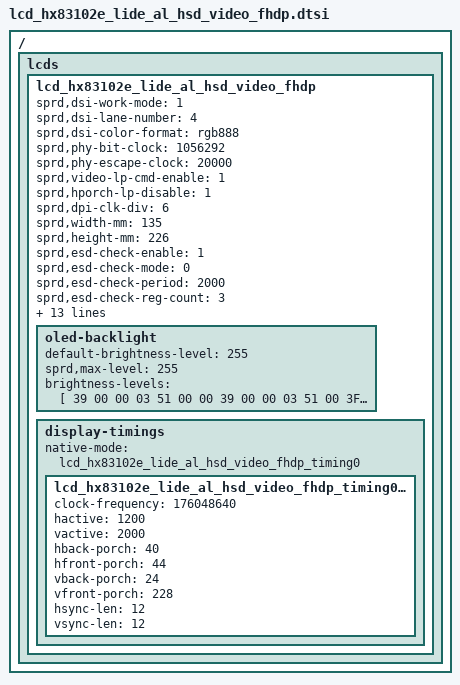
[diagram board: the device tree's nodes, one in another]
/ {
	fragment {
		target-path = "/";
		__overlay__ {
			lcds {
				lcd_hx83102e_lide_al_hsd_video_fhdp: lcd_hx83102e_lide_al_hsd_video_fhdp {

					sprd,dsi-work-mode = <1>; /* video burst mode*/
					sprd,dsi-lane-number = <4>;
					sprd,dsi-color-format = "rgb888";

					sprd,phy-bit-clock = <1056292>;  /* kbps */
					sprd,phy-escape-clock = <20000>;/* kHz */

					sprd,video-lp-cmd-enable = <1>;
					sprd,hporch-lp-disable = <1>;
					sprd,dpi-clk-div = <6>;

					sprd,width-mm = <135>;
					sprd,height-mm = <226>;

					sprd,esd-check-enable = <1>;
					sprd,esd-check-mode = <0>;
					sprd,esd-check-period = <2000>;
					sprd,esd-check-reg-count = <3>;
					sprd,esd-check-register = [0A 09 45];
					sprd,esd-check-value-len = <1 3 1>;
					sprd,esd-check-value = [9D 80 73 06 08];

					sprd,reset-on-sequence = <1 5>, <0 15>, <1 30>;
					sprd,reset-off-sequence = <1 5>;

					sprd,initial-command = [
						39 01 00 04 B9 83 10 2E
						39 01 00 03 E1 00 00
						39 01 00 02 E2 03
						39 01 00 02 E9 CD
						39 01 00 02 BB 01
						39 01 00 02 E9 00
						39 01 00 05 D1 67 0C FF 05
						39 01 00 12 B1 10 FA AF AF 31 31 B1 6C 31 36 36 36 36 22 21 15 00
						39 01 00 11 B2 00 B0 47 D0 00 22 E4 26 20 00 00 00 15 20 57 00
						39 01 00 11 B4 10 10 01 01 88 70 68 50 08 8F 07 58 00 FF 00 FF
						39 01 00 03 D2 31 31
						39 01 00 08 BF FC 85 80 9C 36 00 1C
						39 01 00 2C D3 00 00 00 00 3C 3D 00 00 00 27 27 22 0F 23 23 04 00 32 10 21 00 21 32 17 F5 07 F5 32 10 08 00 00 00 00 2B 50 B6 C8 2C 4F B6 C8 0F
						39 01 00 2F E0 00 09 18 22 2B 50 67 6E 72 6C 80 81 81 8C 87 8F 98 AC AB 54 5B 66 73 00 09 18 22 2B 50 67 6E 72 6C 80 81 81 8C 87 8F 98 AC AB 54 5B 66 73
						39 01 00 02 BD 01
						39 01 00 0A CB 80 36 12 16 C0 28 54 84 22
						39 01 00 0C D3 01 00 F8 00 00 11 10 00 0A 00 01
						39 01 00 02 BD 02
						39 01 00 07 B4 4E 00 33 11 33 88
						39 01 00 04 BF F2 00 02
						39 01 00 02 BD 00
						39 01 00 0F C0 27 27 44 11 A2 17 00 86 00 00 00 00 63 63
						39 01 00 2D D5 18 18 18 18 18 18 18 18 18 18 19 19 3A 3A 1A 1A 1B 1B 00 01 02 03 04 05 06 07 20 21 24 25 18 18 18 18 18 18 18 18 18 18 18 18 18 18
						39 01 00 2D D6 18 18 18 18 18 18 18 18 18 18 3A 3A 19 19 1A 1A 1B 1B 07 06 05 04 03 02 01 00 25 24 21 20 18 18 18 18 18 18 18 18 18 18 18 18 18 18
						39 01 00 04 D0 07 04 05
						39 01 00 18 E7 12 13 02 02 55 00 0E 0E 00 26 29 72 1C 72 01 27 00 00 00 00 17 00 68
						39 01 00 02 BD 01
						39 01 00 08 E7 01 30 01 94 0D B5 0E
						39 01 00 02 BD 02
						39 01 00 1D E7 FF 01 FD 01 00 00 22 00 00 00 00 00 00 00 00 00 00 00 00 00 00 00 00 00 81 00 02 40
						39 01 00 02 BD 01
						39 01 00 0D D8 FF FF FF FF FF F0 FF FF FF FF FF F0
						39 01 00 02 BD 02
						39 01 00 0D D8 FF FF FF FF FF F0 FF FF FF FF FF F0
						39 01 00 02 BD 00
						39 01 00 02 CC 0E	//old 02 Display flip 180 degrees 0E
						39 01 00 09 BA 70 03 A8 83 F2 00 C0 0D
						39 01 00 02 BD 03
						39 01 00 02 B2 80
						39 01 00 02 BD 00
						39 01 00 07 C8 00 04 04 00 00 82
						39 01 00 02 BD 00
						39 01 00 02 53 2C
						39 01 00 04 C9 00 0C 3A
						39 01 00 02 35 00
						39 01 00 04 B9 00 00 00
						05 46 00 01 11
						05 14 00 01 29
						];
					sprd,sleep-in-command = [
						39  00 00 04 B9 83 10 2E
						39  00 00 12 B1 10 FA AF AF 31 31 B1 00 31 36 36 36 36 22 21 15 00
						05  14 00 01 28
						05  46 00 01 10
						];
					sprd,deep-sleep-in-command = [
						39  00 00 04 B9 83 10 2E
						39  00 00 12 B1 10 FA AF AF 31 31 B1 00 31 36 36 36 36 22 21 15 00
						05  14 00 02 28 00
						05  46 00 02 10 00
						39  00 00 04 B9 83 10 2E
						15  14 00 02 B1 11
						];
					sprd,sleep-out-command = [
						23 78 00 01 11
						23 14 00 01 29
						];

					oled-backlight {
						default-brightness-level = <255>;
						sprd,max-level = <255>;

						brightness-levels = [
							39 00 00 03 51 00 00
							39 00 00 03 51 00 3F
							39 00 00 03 51 00 3F
							39 00 00 03 51 00 3F
							39 00 00 03 51 00 4F
							39 00 00 03 51 00 5F
							39 00 00 03 51 00 6F
							39 00 00 03 51 00 7F
							39 00 00 03 51 00 8F
							39 00 00 03 51 00 9F
							39 00 00 03 51 00 AF
							39 00 00 03 51 00 BF
							39 00 00 03 51 00 CF
							39 00 00 03 51 00 DF
							39 00 00 03 51 00 EF
							39 00 00 03 51 00 FF
							39 00 00 03 51 01 0F
							39 00 00 03 51 01 1F
							39 00 00 03 51 01 2F
							39 00 00 03 51 01 3F
							39 00 00 03 51 01 4F
							39 00 00 03 51 01 5F
							39 00 00 03 51 01 6F
							39 00 00 03 51 01 7F
							39 00 00 03 51 01 8F
							39 00 00 03 51 01 9F
							39 00 00 03 51 01 AF
							39 00 00 03 51 01 BF
							39 00 00 03 51 01 CF
							39 00 00 03 51 01 DF
							39 00 00 03 51 01 EF
							39 00 00 03 51 01 FF
							39 00 00 03 51 02 0F
							39 00 00 03 51 02 1F
							39 00 00 03 51 02 2F
							39 00 00 03 51 02 3F
							39 00 00 03 51 02 4F
							39 00 00 03 51 02 5F
							39 00 00 03 51 02 6F
							39 00 00 03 51 02 7F
							39 00 00 03 51 02 8F
							39 00 00 03 51 02 9F
							39 00 00 03 51 02 AF
							39 00 00 03 51 02 BF
							39 00 00 03 51 02 CF
							39 00 00 03 51 02 DF
							39 00 00 03 51 02 EF
							39 00 00 03 51 02 FF
							39 00 00 03 51 03 0F
							39 00 00 03 51 03 1F
							39 00 00 03 51 03 2F
							39 00 00 03 51 03 3F
							39 00 00 03 51 03 4F
							39 00 00 03 51 03 5F
							39 00 00 03 51 03 6F
							39 00 00 03 51 03 7F
							39 00 00 03 51 03 8F
							39 00 00 03 51 03 9F
							39 00 00 03 51 03 AF
							39 00 00 03 51 03 BF
							39 00 00 03 51 03 CF
							39 00 00 03 51 03 DF
							39 00 00 03 51 03 EF
							39 00 00 03 51 03 FF
							39 00 00 03 51 04 0F
							39 00 00 03 51 04 1F
							39 00 00 03 51 04 2F
							39 00 00 03 51 04 3F
							39 00 00 03 51 04 4F
							39 00 00 03 51 04 5F
							39 00 00 03 51 04 6F
							39 00 00 03 51 04 7F
							39 00 00 03 51 04 8F
							39 00 00 03 51 04 9F
							39 00 00 03 51 04 AF
							39 00 00 03 51 04 BF
							39 00 00 03 51 04 CF
							39 00 00 03 51 04 DF
							39 00 00 03 51 04 EF
							39 00 00 03 51 04 FF
							39 00 00 03 51 05 0F
							39 00 00 03 51 05 1F
							39 00 00 03 51 05 2F
							39 00 00 03 51 05 3F
							39 00 00 03 51 05 4F
							39 00 00 03 51 05 5F
							39 00 00 03 51 05 6F
							39 00 00 03 51 05 7F
							39 00 00 03 51 05 8F
							39 00 00 03 51 05 9F
							39 00 00 03 51 05 AF
							39 00 00 03 51 05 BF
							39 00 00 03 51 05 CF
							39 00 00 03 51 05 DF
							39 00 00 03 51 05 EF
							39 00 00 03 51 05 FF
							39 00 00 03 51 06 0F
							39 00 00 03 51 06 1F
							39 00 00 03 51 06 2F
							39 00 00 03 51 06 3F
							39 00 00 03 51 06 4F
							39 00 00 03 51 06 5F
							39 00 00 03 51 06 6F
							39 00 00 03 51 06 7F
							39 00 00 03 51 06 8F
							39 00 00 03 51 06 9F
							39 00 00 03 51 06 AF
							39 00 00 03 51 06 BF
							39 00 00 03 51 06 CF
							39 00 00 03 51 06 DF
							39 00 00 03 51 06 EF
							39 00 00 03 51 06 FF
							39 00 00 03 51 07 0F
							39 00 00 03 51 07 1F
							39 00 00 03 51 07 2F
							39 00 00 03 51 07 3F
							39 00 00 03 51 07 4F
							39 00 00 03 51 07 5F
							39 00 00 03 51 07 6F
							39 00 00 03 51 07 7F
							39 00 00 03 51 07 8F
							39 00 00 03 51 07 9F
							39 00 00 03 51 07 AF
							39 00 00 03 51 07 BF
							39 00 00 03 51 07 CF
							39 00 00 03 51 07 DF
							39 00 00 03 51 07 EF
							39 00 00 03 51 07 FF
							39 00 00 03 51 08 0F
							39 00 00 03 51 08 1F
							39 00 00 03 51 08 2F
							39 00 00 03 51 08 3F
							39 00 00 03 51 08 4F
							39 00 00 03 51 08 5F
							39 00 00 03 51 08 6F
							39 00 00 03 51 08 7F
							39 00 00 03 51 08 8F
							39 00 00 03 51 08 9F
							39 00 00 03 51 08 AF
							39 00 00 03 51 08 BF
							39 00 00 03 51 08 CF
							39 00 00 03 51 08 DF
							39 00 00 03 51 08 EF
							39 00 00 03 51 08 FF
							39 00 00 03 51 09 0F
							39 00 00 03 51 09 1F
							39 00 00 03 51 09 2F
							39 00 00 03 51 09 3F
							39 00 00 03 51 09 4F
							39 00 00 03 51 09 5F
							39 00 00 03 51 09 6F
							39 00 00 03 51 09 7F
							39 00 00 03 51 09 8F
							39 00 00 03 51 09 9F
							39 00 00 03 51 09 AF
							39 00 00 03 51 09 BF
							39 00 00 03 51 09 CF
							39 00 00 03 51 09 DF
							39 00 00 03 51 09 EF
							39 00 00 03 51 09 FF
							39 00 00 03 51 0A 0F
							39 00 00 03 51 0A 1F
							39 00 00 03 51 0A 2F
							39 00 00 03 51 0A 3F
							39 00 00 03 51 0A 4F
							39 00 00 03 51 0A 5F
							39 00 00 03 51 0A 6F
							39 00 00 03 51 0A 7F
							39 00 00 03 51 0A 8F
							39 00 00 03 51 0A 9F
							39 00 00 03 51 0A AF
							39 00 00 03 51 0A BF
							39 00 00 03 51 0A CF
							39 00 00 03 51 0A DF
							39 00 00 03 51 0A EF
							39 00 00 03 51 0A FF
							39 00 00 03 51 0B 0F
							39 00 00 03 51 0B 1F
							39 00 00 03 51 0B 2F
							39 00 00 03 51 0B 3F
							39 00 00 03 51 0B 4F
							39 00 00 03 51 0B 5F
							39 00 00 03 51 0B 6F
							39 00 00 03 51 0B 7F
							39 00 00 03 51 0B 8F
							39 00 00 03 51 0B 9F
							39 00 00 03 51 0B AF
							39 00 00 03 51 0B BF
							39 00 00 03 51 0B CF
							39 00 00 03 51 0B DF
							39 00 00 03 51 0B EF
							39 00 00 03 51 0B FF
							39 00 00 03 51 0C 0F
							39 00 00 03 51 0C 1F
							39 00 00 03 51 0C 2F
							39 00 00 03 51 0C 3F
							39 00 00 03 51 0C 4F
							39 00 00 03 51 0C 5F
							39 00 00 03 51 0C 6F
							39 00 00 03 51 0C 7F
							39 00 00 03 51 0C 8F
							39 00 00 03 51 0C 9F
							39 00 00 03 51 0C AF
							39 00 00 03 51 0C BF
							39 00 00 03 51 0C CF
							39 00 00 03 51 0C DF
							39 00 00 03 51 0C EF
							39 00 00 03 51 0C FF
							39 00 00 03 51 0D 0F
							39 00 00 03 51 0D 1F
							39 00 00 03 51 0D 2F
							39 00 00 03 51 0D 3F
							39 00 00 03 51 0D 4F
							39 00 00 03 51 0D 5F
							39 00 00 03 51 0D 6F
							39 00 00 03 51 0D 7F
							39 00 00 03 51 0D 8F
							39 00 00 03 51 0D 9F
							39 00 00 03 51 0D AF
							39 00 00 03 51 0D BF
							39 00 00 03 51 0D CF
							39 00 00 03 51 0D DF
							39 00 00 03 51 0D EF
							39 00 00 03 51 0D FF
							39 00 00 03 51 0E 0F
							39 00 00 03 51 0E 1F
							39 00 00 03 51 0E 2F
							39 00 00 03 51 0E 3F
							39 00 00 03 51 0E 4F
							39 00 00 03 51 0E 5F
							39 00 00 03 51 0E 6F
							39 00 00 03 51 0E 7F
							39 00 00 03 51 0E 8F
							39 00 00 03 51 0E 9F
							39 00 00 03 51 0E AF
							39 00 00 03 51 0E BF
							39 00 00 03 51 0E CF
							39 00 00 03 51 0E DF
							39 00 00 03 51 0E EF
							39 00 00 03 51 0E FF
							39 00 00 03 51 0F 0F
							39 00 00 03 51 0F 1F
							39 00 00 03 51 0F 2F
							39 00 00 03 51 0F 3F
							39 00 00 03 51 0F 4F
							39 00 00 03 51 0F 5F
							39 00 00 03 51 0F 6F
							39 00 00 03 51 0F 7F
							39 00 00 03 51 0F 8F
							39 00 00 03 51 0F 9F
							39 00 00 03 51 0F AF
							39 00 00 03 51 0F BF
							39 00 00 03 51 0F CF
							39 00 00 03 51 0F DF
							39 00 00 03 51 0F EF
							39 00 00 03 51 0F FF
							];
					};


					display-timings {
						native-mode = <&lcd_hx83102e_lide_al_hsd_video_fhdp_timing0>;

						lcd_hx83102e_lide_al_hsd_video_fhdp_timing0: timing0 {
							clock-frequency = <176048640>;
							hactive = <1200>;
							vactive = <2000>;
							hback-porch = <40>;
							hfront-porch = <44>;
							vback-porch = <24>;
							vfront-porch = <228>;
							hsync-len = <12>;
							vsync-len = <12>;
						};
					};
				};
			};
		};
	};
};
